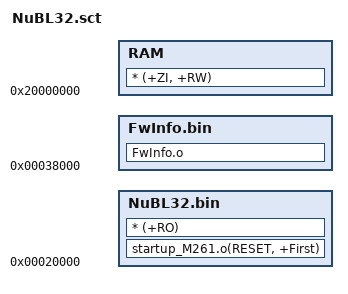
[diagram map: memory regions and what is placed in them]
NUBL32 0x20000  ; located in 128K
{
    NuBL32.bin +0
    {
        startup_M261.o(RESET, +First)
        * (+RO)
    }
    
    RAM 0x20000000
    {
        * (+ZI, +RW)
    }
}

NUBL32_INFO 0x38000 ; located in 224K
{
    FwInfo.bin +0
    {
        FwInfo.o
    }
}
